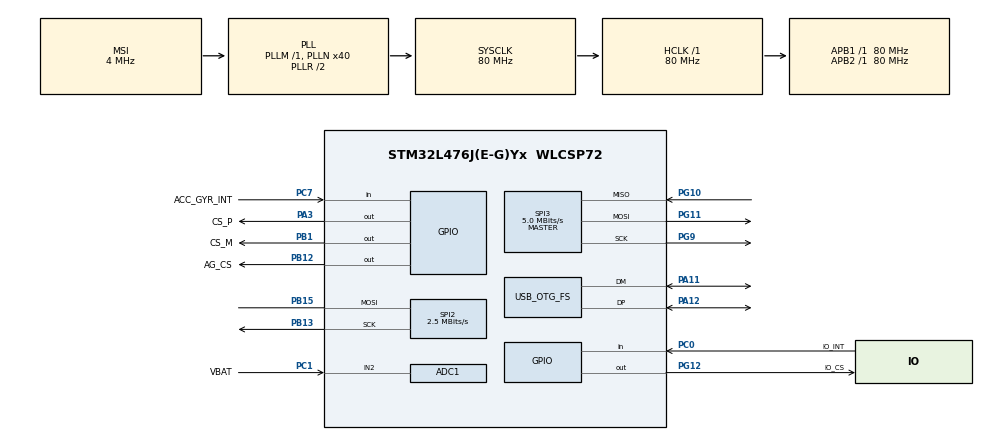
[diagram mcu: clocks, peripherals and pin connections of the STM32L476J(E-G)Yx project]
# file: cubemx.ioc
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ADC1.Channel-0\#ChannelRegularConversion=ADC_CHANNEL_2
ADC1.ClockPrescaler=ADC_CLOCK_ASYNC_DIV64
ADC1.NbrOfConversionFlag=1
ADC1.OffsetNumber-0\#ChannelRegularConversion=ADC_OFFSET_NONE
ADC1.Rank-0\#ChannelRegularConversion=1
ADC1.SamplingTime-0\#ChannelRegularConversion=ADC_SAMPLETIME_2CYCLES_5
ADC1.master=1
FREERTOS.Tasks01=defaultTask,24,128,StartDefaultTask,Default,NULL,Dynamic,NULL,NULL
FREERTOS.configENABLE_FPU=1
FREERTOS.configGENERATE_RUN_TIME_STATS=1
FREERTOS.configTOTAL_HEAP_SIZE=10000
FREERTOS.configUSE_STATS_FORMATTING_FUNCTIONS=1
Mcu.Family=STM32L4
Mcu.Name=STM32L476J(E-G)Yx
Mcu.Package=WLCSP72
NVIC.ADC1_2_IRQn=true\:5\:0\:false\:false\:true\:true\:true\:true
NVIC.OTG_FS_IRQn=true\:5\:0\:false\:false\:true\:true\:true\:true
NVIC.PriorityGroup=NVIC_PRIORITYGROUP_4
NVIC.SPI3_IRQn=true\:5\:0\:false\:false\:true\:true\:true\:true
NVIC.TIM2_IRQn=true\:0\:0\:false\:false\:true\:false\:false\:true
NVIC.TimeBase=TIM2_IRQn
NVIC.TimeBaseIP=TIM2
PA11.Mode=Device_Only
PA11.Signal=USB_OTG_FS_DM
PA12.Mode=Device_Only
PA12.Signal=USB_OTG_FS_DP
PA13\ (JTMS-SWDIO).Mode=Serial_Wire
PA13\ (JTMS-SWDIO).Signal=SYS_JTMS-SWDIO
PA14\ (JTCK-SWCLK).Mode=Serial_Wire
PA14\ (JTCK-SWCLK).Signal=SYS_JTCK-SWCLK
PA3.GPIO_Label=CS_P
PA3.Signal=GPIO_Output
PB1.GPIO_Label=CS_M
PB1.Signal=GPIO_Output
PB12.GPIO_Label=AG_CS
PB12.Signal=GPIO_Output
PB13.Mode=Simplex_Bidirectional_Master
PB13.Signal=SPI2_SCK
PB15.Mode=Simplex_Bidirectional_Master
PB15.Signal=SPI2_MOSI
PC0.GPIO_Label=IO_INT
PC0.Signal=GPIO_Input
PC1.GPIO_Label=VBAT
PC1.Signal=ADCx_IN2
PC7.GPIO_Label=ACC_GYR_INT
PC7.Signal=GPIO_Input
PG10.Mode=Full_Duplex_Master
PG10.Signal=SPI3_MISO
PG11.Mode=Full_Duplex_Master
PG11.Signal=SPI3_MOSI
PG12.GPIO_Label=IO_CS
PG12.Signal=GPIO_Output
PG9.Mode=Full_Duplex_Master
PG9.Signal=SPI3_SCK
ProjectManager.HeapSize=0x200
ProjectManager.StackSize=0x400
ProjectManager.TargetToolchain=Makefile
RCC.ADCFreq_Value=48000000
RCC.AHBFreq_Value=80000000
RCC.APB1Freq_Value=80000000
RCC.APB1TimFreq_Value=80000000
RCC.APB2Freq_Value=80000000
RCC.APB2TimFreq_Value=80000000
RCC.CortexFreq_Value=80000000
RCC.HCLKFreq_Value=80000000
RCC.HSE_VALUE=8000000
RCC.HSI_VALUE=16000000
RCC.LSE_VALUE=32768
RCC.MSI_VALUE=4000000
RCC.PLLN=40
RCC.PLLSAI1N=24
RCC.SYSCLKFreq_VALUE=80000000
RCC.SYSCLKSource=RCC_SYSCLKSOURCE_PLLCLK
RCC.USBFreq_Value=48000000
RCC.VCOOutputFreq_Value=160000000
SH.ADCx_IN2.0=ADC1_IN2,IN2-Single-Ended
SPI2.BaudRatePrescaler=SPI_BAUDRATEPRESCALER_32
SPI2.CLKPhase=SPI_PHASE_2EDGE
SPI2.CLKPolarity=SPI_POLARITY_HIGH
SPI2.CalculateBaudRate=2.5 MBits/s
SPI2.DataSize=SPI_DATASIZE_8BIT
SPI2.Direction=SPI_DIRECTION_1LINE
SPI2.Mode=SPI_MODE_MASTER
SPI2.VirtualType=VM_MASTER
SPI3.BaudRatePrescaler=SPI_BAUDRATEPRESCALER_16
SPI3.CalculateBaudRate=5.0 MBits/s
SPI3.DataSize=SPI_DATASIZE_8BIT
SPI3.Direction=SPI_DIRECTION_2LINES
SPI3.Mode=SPI_MODE_MASTER
SPI3.VirtualType=VM_MASTER
USB_DEVICE.CLASS_NAME_FS=CDC
USB_DEVICE.VirtualMode=Cdc
USB_DEVICE.VirtualModeFS=Cdc_FS
USB_OTG_FS.VirtualMode=Device_Only
VP_CRC_VS_CRC.Mode=CRC_Activate
VP_FREERTOS_VS_CMSIS_V2.Mode=CMSIS_V2
VP_RNG_VS_RNG.Mode=RNG_Activate
VP_SYS_VS_tim2.Mode=TIM2
VP_TIM1_VS_ClockSourceINT.Mode=Internal
VP_USB_DEVICE_VS_USB_DEVICE_CDC_FS.Mode=CDC_FS
board=custom

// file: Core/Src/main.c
/* USER CODE BEGIN Header */
/**
  ******************************************************************************
  * @file           : main.c
  * @brief          : Main program body
  ******************************************************************************
  * @attention
  *
  * <h2><center>&copy; Copyright (c) 2021 STMicroelectronics.
  * All rights reserved.</center></h2>
  *
  * This software component is licensed by ST under Ultimate Liberty license
  * SLA0044, the "License"; You may not use this file except in compliance with
  * the License. You may obtain a copy of the License at:
  *                             www.st.com/SLA0044
  *
  ******************************************************************************
  */
/* USER CODE END Header */
#include "main.h"
#include "cmsis_os.h"
#include "usb_device.h"
#include "usb_device.h"

/* USER CODE BEGIN Includes */
#include "user_tasks.h"
#include "gong_io.h"
/* USER CODE END Includes */

ADC_HandleTypeDef hadc1;

CRC_HandleTypeDef hcrc;

RNG_HandleTypeDef hrng;

SPI_HandleTypeDef hspi2;
SPI_HandleTypeDef hspi3;

TIM_HandleTypeDef htim1;

/* Definitions for defaultTask */
osThreadId_t defaultTaskHandle;
const osThreadAttr_t defaultTask_attributes = {
  .name = "defaultTask",
  .stack_size = 128 * 4,
  .priority = (osPriority_t) osPriorityNormal,
};

void SystemClock_Config(void);
void PeriphCommonClock_Config(void);
static void MX_GPIO_Init(void);
static void MX_ADC1_Init(void);
static void MX_CRC_Init(void);
static void MX_RNG_Init(void);
static void MX_SPI2_Init(void);
static void MX_TIM1_Init(void);
static void MX_SPI3_Init(void);
void StartDefaultTask(void *argument);

int main(void)
{

  /* MCU Configuration--------------------------------------------------------*/

  /* Reset of all peripherals, Initializes the Flash interface and the Systick. */
  HAL_Init();

  /* Configure the system clock */
  SystemClock_Config();

/* Configure the peripherals common clocks */
  PeriphCommonClock_Config();

  /* Initialize all configured peripherals */
  MX_GPIO_Init();
  MX_ADC1_Init();
  MX_CRC_Init();
  MX_RNG_Init();
  MX_SPI2_Init();
  MX_TIM1_Init();
  MX_SPI3_Init();

  /* Init scheduler */
  osKernelInitialize();

  /* Create the thread(s) */
  /* creation of defaultTask */
  defaultTaskHandle = osThreadNew(StartDefaultTask, NULL, &defaultTask_attributes);

  /* USER CODE BEGIN RTOS_THREADS */
  /* add threads, ... */
  tasks_init();
  /* USER CODE END RTOS_THREADS */

  /* Start scheduler */
  osKernelStart();

  /* We should never get here as control is now taken by the scheduler */
  /* Infinite loop */
  while (1)
  {

  }
}

void SystemClock_Config(void)
{
  RCC_OscInitTypeDef RCC_OscInitStruct = {0};
  RCC_ClkInitTypeDef RCC_ClkInitStruct = {0};

  /** Configure the main internal regulator output voltage
  */
  if (HAL_PWREx_ControlVoltageScaling(PWR_REGULATOR_VOLTAGE_SCALE1) != HAL_OK)
  {
    Error_Handler();
  }
  /** Initializes the RCC Oscillators according to the specified parameters
  * in the RCC_OscInitTypeDef structure.
  */
  RCC_OscInitStruct.OscillatorType = RCC_OSCILLATORTYPE_MSI;
  RCC_OscInitStruct.MSIState = RCC_MSI_ON;
  RCC_OscInitStruct.MSICalibrationValue = 0;
  RCC_OscInitStruct.MSIClockRange = RCC_MSIRANGE_6;
  RCC_OscInitStruct.PLL.PLLState = RCC_PLL_ON;
  RCC_OscInitStruct.PLL.PLLSource = RCC_PLLSOURCE_MSI;
  RCC_OscInitStruct.PLL.PLLM = 1;
  RCC_OscInitStruct.PLL.PLLN = 40;
  RCC_OscInitStruct.PLL.PLLP = RCC_PLLP_DIV7;
  RCC_OscInitStruct.PLL.PLLQ = RCC_PLLQ_DIV2;
  RCC_OscInitStruct.PLL.PLLR = RCC_PLLR_DIV2;
  if (HAL_RCC_OscConfig(&RCC_OscInitStruct) != HAL_OK)
  {
    Error_Handler();
  }
  /** Initializes the CPU, AHB and APB buses clocks
  */
  RCC_ClkInitStruct.ClockType = RCC_CLOCKTYPE_HCLK|RCC_CLOCKTYPE_SYSCLK
                              |RCC_CLOCKTYPE_PCLK1|RCC_CLOCKTYPE_PCLK2;
  RCC_ClkInitStruct.SYSCLKSource = RCC_SYSCLKSOURCE_PLLCLK;
  RCC_ClkInitStruct.AHBCLKDivider = RCC_SYSCLK_DIV1;
  RCC_ClkInitStruct.APB1CLKDivider = RCC_HCLK_DIV1;
  RCC_ClkInitStruct.APB2CLKDivider = RCC_HCLK_DIV1;

  if (HAL_RCC_ClockConfig(&RCC_ClkInitStruct, FLASH_LATENCY_4) != HAL_OK)
  {
    Error_Handler();
  }
}

void PeriphCommonClock_Config(void)
{
  RCC_PeriphCLKInitTypeDef PeriphClkInit = {0};

  /** Initializes the peripherals clock
  */
  PeriphClkInit.PeriphClockSelection = RCC_PERIPHCLK_USB|RCC_PERIPHCLK_RNG
                              |RCC_PERIPHCLK_ADC;
  PeriphClkInit.AdcClockSelection = RCC_ADCCLKSOURCE_PLLSAI1;
  PeriphClkInit.UsbClockSelection = RCC_USBCLKSOURCE_PLLSAI1;
  PeriphClkInit.RngClockSelection = RCC_RNGCLKSOURCE_PLLSAI1;
  PeriphClkInit.PLLSAI1.PLLSAI1Source = RCC_PLLSOURCE_MSI;
  PeriphClkInit.PLLSAI1.PLLSAI1M = 1;
  PeriphClkInit.PLLSAI1.PLLSAI1N = 24;
  PeriphClkInit.PLLSAI1.PLLSAI1P = RCC_PLLP_DIV7;
  PeriphClkInit.PLLSAI1.PLLSAI1Q = RCC_PLLQ_DIV2;
  PeriphClkInit.PLLSAI1.PLLSAI1R = RCC_PLLR_DIV2;
  PeriphClkInit.PLLSAI1.PLLSAI1ClockOut = RCC_PLLSAI1_48M2CLK|RCC_PLLSAI1_ADC1CLK;
  if (HAL_RCCEx_PeriphCLKConfig(&PeriphClkInit) != HAL_OK)
  {
    Error_Handler();
  }
}

static void MX_ADC1_Init(void)
{

  ADC_MultiModeTypeDef multimode = {0};
  ADC_ChannelConfTypeDef sConfig = {0};

  /** Common config
  */
  hadc1.Instance = ADC1;
  hadc1.Init.ClockPrescaler = ADC_CLOCK_ASYNC_DIV64;
  hadc1.Init.Resolution = ADC_RESOLUTION_12B;
  hadc1.Init.DataAlign = ADC_DATAALIGN_RIGHT;
  hadc1.Init.ScanConvMode = ADC_SCAN_DISABLE;
  hadc1.Init.EOCSelection = ADC_EOC_SINGLE_CONV;
  hadc1.Init.LowPowerAutoWait = DISABLE;
  hadc1.Init.ContinuousConvMode = DISABLE;
  hadc1.Init.NbrOfConversion = 1;
  hadc1.Init.DiscontinuousConvMode = DISABLE;
  hadc1.Init.ExternalTrigConv = ADC_SOFTWARE_START;
  hadc1.Init.ExternalTrigConvEdge = ADC_EXTERNALTRIGCONVEDGE_NONE;
  hadc1.Init.DMAContinuousRequests = DISABLE;
  hadc1.Init.Overrun = ADC_OVR_DATA_PRESERVED;
  hadc1.Init.OversamplingMode = DISABLE;
  if (HAL_ADC_Init(&hadc1) != HAL_OK)
  {
    Error_Handler();
  }
  /** Configure the ADC multi-mode
  */
  multimode.Mode = ADC_MODE_INDEPENDENT;
  if (HAL_ADCEx_MultiModeConfigChannel(&hadc1, &multimode) != HAL_OK)
  {
    Error_Handler();
  }
  /** Configure Regular Channel
  */
  sConfig.Channel = ADC_CHANNEL_2;
  sConfig.Rank = ADC_REGULAR_RANK_1;
  sConfig.SamplingTime = ADC_SAMPLETIME_2CYCLES_5;
  sConfig.SingleDiff = ADC_SINGLE_ENDED;
  sConfig.OffsetNumber = ADC_OFFSET_NONE;
  sConfig.Offset = 0;
  if (HAL_ADC_ConfigChannel(&hadc1, &sConfig) != HAL_OK)
  {
    Error_Handler();
  }

}

static void MX_CRC_Init(void)
{

  hcrc.Instance = CRC;
  hcrc.Init.DefaultPolynomialUse = DEFAULT_POLYNOMIAL_ENABLE;
  hcrc.Init.DefaultInitValueUse = DEFAULT_INIT_VALUE_ENABLE;
  hcrc.Init.InputDataInversionMode = CRC_INPUTDATA_INVERSION_NONE;
  hcrc.Init.OutputDataInversionMode = CRC_OUTPUTDATA_INVERSION_DISABLE;
  hcrc.InputDataFormat = CRC_INPUTDATA_FORMAT_BYTES;
  if (HAL_CRC_Init(&hcrc) != HAL_OK)
  {
    Error_Handler();
  }

}

static void MX_RNG_Init(void)
{

  hrng.Instance = RNG;
  if (HAL_RNG_Init(&hrng) != HAL_OK)
  {
    Error_Handler();
  }

}

static void MX_SPI2_Init(void)
{

  /* SPI2 parameter configuration*/
  hspi2.Instance = SPI2;
  hspi2.Init.Mode = SPI_MODE_MASTER;
  hspi2.Init.Direction = SPI_DIRECTION_1LINE;
  hspi2.Init.DataSize = SPI_DATASIZE_8BIT;
  hspi2.Init.CLKPolarity = SPI_POLARITY_HIGH;
  hspi2.Init.CLKPhase = SPI_PHASE_2EDGE;
  hspi2.Init.NSS = SPI_NSS_SOFT;
  hspi2.Init.BaudRatePrescaler = SPI_BAUDRATEPRESCALER_32;
  hspi2.Init.FirstBit = SPI_FIRSTBIT_MSB;
  hspi2.Init.TIMode = SPI_TIMODE_DISABLE;
  hspi2.Init.CRCCalculation = SPI_CRCCALCULATION_DISABLE;
  hspi2.Init.CRCPolynomial = 7;
  hspi2.Init.CRCLength = SPI_CRC_LENGTH_DATASIZE;
  hspi2.Init.NSSPMode = SPI_NSS_PULSE_DISABLE;
  if (HAL_SPI_Init(&hspi2) != HAL_OK)
  {
    Error_Handler();
  }

}

static void MX_SPI3_Init(void)
{

  /* SPI3 parameter configuration*/
  hspi3.Instance = SPI3;
  hspi3.Init.Mode = SPI_MODE_MASTER;
  hspi3.Init.Direction = SPI_DIRECTION_2LINES;
  hspi3.Init.DataSize = SPI_DATASIZE_8BIT;
  hspi3.Init.CLKPolarity = SPI_POLARITY_LOW;
  hspi3.Init.CLKPhase = SPI_PHASE_1EDGE;
  hspi3.Init.NSS = SPI_NSS_SOFT;
  hspi3.Init.BaudRatePrescaler = SPI_BAUDRATEPRESCALER_16;
  hspi3.Init.FirstBit = SPI_FIRSTBIT_MSB;
  hspi3.Init.TIMode = SPI_TIMODE_DISABLE;
  hspi3.Init.CRCCalculation = SPI_CRCCALCULATION_DISABLE;
  hspi3.Init.CRCPolynomial = 7;
  hspi3.Init.CRCLength = SPI_CRC_LENGTH_DATASIZE;
  hspi3.Init.NSSPMode = SPI_NSS_PULSE_ENABLE;
  if (HAL_SPI_Init(&hspi3) != HAL_OK)
  {
    Error_Handler();
  }

}

static void MX_TIM1_Init(void)
{

  TIM_ClockConfigTypeDef sClockSourceConfig = {0};
  TIM_MasterConfigTypeDef sMasterConfig = {0};

  htim1.Instance = TIM1;
  htim1.Init.Prescaler = 0;
  htim1.Init.CounterMode = TIM_COUNTERMODE_UP;
  htim1.Init.Period = 65535;
  htim1.Init.ClockDivision = TIM_CLOCKDIVISION_DIV1;
  htim1.Init.RepetitionCounter = 0;
  htim1.Init.AutoReloadPreload = TIM_AUTORELOAD_PRELOAD_DISABLE;
  if (HAL_TIM_Base_Init(&htim1) != HAL_OK)
  {
    Error_Handler();
  }
  sClockSourceConfig.ClockSource = TIM_CLOCKSOURCE_INTERNAL;
  if (HAL_TIM_ConfigClockSource(&htim1, &sClockSourceConfig) != HAL_OK)
  {
    Error_Handler();
  }
  sMasterConfig.MasterOutputTrigger = TIM_TRGO_RESET;
  sMasterConfig.MasterOutputTrigger2 = TIM_TRGO2_RESET;
  sMasterConfig.MasterSlaveMode = TIM_MASTERSLAVEMODE_DISABLE;
  if (HAL_TIMEx_MasterConfigSynchronization(&htim1, &sMasterConfig) != HAL_OK)
  {
    Error_Handler();
  }

}

static void MX_GPIO_Init(void)
{
  GPIO_InitTypeDef GPIO_InitStruct = {0};

  /* GPIO Ports Clock Enable */
  __HAL_RCC_GPIOG_CLK_ENABLE();
  HAL_PWREx_EnableVddIO2();
  __HAL_RCC_GPIOA_CLK_ENABLE();
  __HAL_RCC_GPIOC_CLK_ENABLE();
  __HAL_RCC_GPIOB_CLK_ENABLE();

  /*Configure GPIO pin Output Level */
  HAL_GPIO_WritePin(IO_CS_GPIO_Port, IO_CS_Pin, GPIO_PIN_RESET);

  /*Configure GPIO pin Output Level */
  HAL_GPIO_WritePin(GPIOB, AG_CS_Pin|CS_M_Pin, GPIO_PIN_RESET);

  /*Configure GPIO pin Output Level */
  HAL_GPIO_WritePin(CS_P_GPIO_Port, CS_P_Pin, GPIO_PIN_RESET);

  /*Configure GPIO pin : IO_CS_Pin */
  GPIO_InitStruct.Pin = IO_CS_Pin;
  GPIO_InitStruct.Mode = GPIO_MODE_OUTPUT_PP;
  GPIO_InitStruct.Pull = GPIO_NOPULL;
  GPIO_InitStruct.Speed = GPIO_SPEED_FREQ_LOW;
  HAL_GPIO_Init(IO_CS_GPIO_Port, &GPIO_InitStruct);

  /*Configure GPIO pins : ACC_GYR_INT_Pin IO_INT_Pin */
  GPIO_InitStruct.Pin = ACC_GYR_INT_Pin|IO_INT_Pin;
  GPIO_InitStruct.Mode = GPIO_MODE_INPUT;
  GPIO_InitStruct.Pull = GPIO_NOPULL;
  HAL_GPIO_Init(GPIOC, &GPIO_InitStruct);

  /*Configure GPIO pins : AG_CS_Pin CS_M_Pin */
  GPIO_InitStruct.Pin = AG_CS_Pin|CS_M_Pin;
  GPIO_InitStruct.Mode = GPIO_MODE_OUTPUT_PP;
  GPIO_InitStruct.Pull = GPIO_NOPULL;
  GPIO_InitStruct.Speed = GPIO_SPEED_FREQ_LOW;
  HAL_GPIO_Init(GPIOB, &GPIO_InitStruct);

  /*Configure GPIO pin : CS_P_Pin */
  GPIO_InitStruct.Pin = CS_P_Pin;
  GPIO_InitStruct.Mode = GPIO_MODE_OUTPUT_PP;
  GPIO_InitStruct.Pull = GPIO_NOPULL;
  GPIO_InitStruct.Speed = GPIO_SPEED_FREQ_LOW;
  HAL_GPIO_Init(CS_P_GPIO_Port, &GPIO_InitStruct);

}

void StartDefaultTask(void *argument)
{
  /* init code for USB_DEVICE */
  MX_USB_DEVICE_Init();
  /* USER CODE BEGIN 5 */
  // TODO: Place test code here during hardware bringup and driver development
  //gong_io_test_main(&hspi3);
  /* Infinite loop */
  for(;;)
  {
    osDelay(10000);
  }
  /* USER CODE END 5 */
}

void HAL_TIM_PeriodElapsedCallback(TIM_HandleTypeDef *htim)
{
  if (htim->Instance == TIM2) {
    HAL_IncTick();
  }
}

void Error_Handler(void)
{
  __disable_irq();
  while (1)
  {
  }
}

/************************ (C) COPYRIGHT STMicroelectronics *****END OF FILE****/
